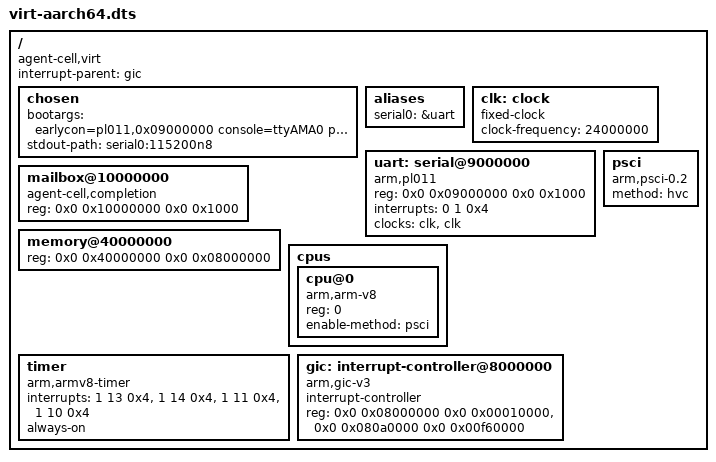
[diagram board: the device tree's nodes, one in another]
/dts-v1/;

/ {
    compatible = "agent-cell,virt";
    #address-cells = <2>;
    #size-cells = <2>;
    interrupt-parent = <&gic>;

    chosen {
        bootargs = "earlycon=pl011,0x09000000 console=ttyAMA0 panic=1 reboot=k rdinit=/init pci=off";
        stdout-path = "serial0:115200n8";
    };

    aliases {
        serial0 = &uart;
    };

    clk: clock {
        compatible = "fixed-clock";
        #clock-cells = <0>;
        clock-frequency = <24000000>;
    };

    uart: serial@9000000 {
        compatible = "arm,pl011", "arm,primecell";
        reg = <0x0 0x09000000 0x0 0x1000>;
        interrupts = <0 1 0x4>;
        clocks = <&clk>, <&clk>;
        clock-names = "uartclk", "apb_pclk";
    };

    mailbox@10000000 {
        compatible = "agent-cell,completion";
        reg = <0x0 0x10000000 0x0 0x1000>;
    };

    memory@40000000 {
        device_type = "memory";
        reg = <0x0 0x40000000 0x0 0x08000000>;
    };

    cpus {
        #address-cells = <1>;
        #size-cells = <0>;
        cpu@0 {
            device_type = "cpu";
            compatible = "arm,arm-v8";
            reg = <0>;
            enable-method = "psci";
        };
    };

    psci {
        compatible = "arm,psci-0.2";
        method = "hvc";
    };

    timer {
        compatible = "arm,armv8-timer";
        interrupts = <1 13 0x4>, <1 14 0x4>, <1 11 0x4>, <1 10 0x4>;
        always-on;
    };

    gic: interrupt-controller@8000000 {
        compatible = "arm,gic-v3";
        #interrupt-cells = <3>;
        interrupt-controller;
        reg = <0x0 0x08000000 0x0 0x00010000>,
              <0x0 0x080a0000 0x0 0x00f60000>;
    };
};
